# PIC18F24Q10 register map
Vendor: Microchip
Registers are 8-bit, read-write, reset 0x0 unless marked. A register's access mark holds for its fields unless they carry their own. Addresses are absolute, and some are shared; only a register's first bit layout is shown; [hi:lo] are bit positions; {n}, {i} and the like mark numbered series.

## math_progcrc
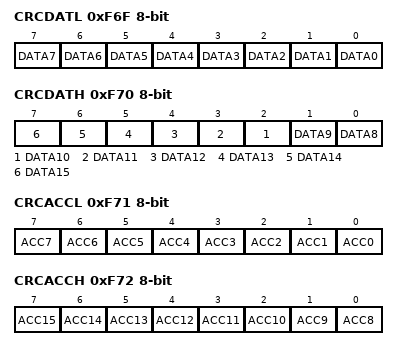
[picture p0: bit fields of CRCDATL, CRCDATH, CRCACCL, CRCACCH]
0xF6F CRCDATL reset not defined — (power-on value xxxxxxxx)
  [n] DATA{n} (n=0..7)
0xF70 CRCDATH reset not defined — (power-on value xxxxxxxx)
  [n-8] DATA{n} (n=8..15)
0xF71 CRCACCL
  [n] ACC{n} (n=0..7)
0xF72 CRCACCH
  [n-8] ACC{n} (n=8..15)
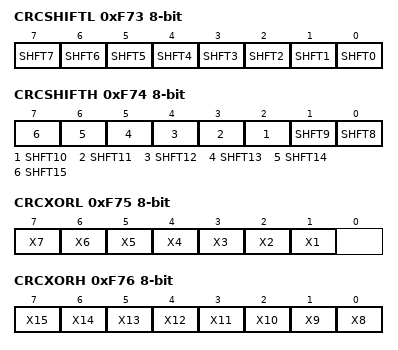
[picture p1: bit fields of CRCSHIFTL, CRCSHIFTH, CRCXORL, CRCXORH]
0xF73 CRCSHIFTL ro
  [n] SHFT{n} (n=0..7)
0xF74 CRCSHIFTH ro
  [n-8] SHFT{n} (n=8..15)
0xF75 CRCXORL reset not defined — (power-on value xxxxxxx1)
  [n] X{n} (n=1..7)
0xF76 CRCXORH reset not defined — (power-on value xxxxxxxx)
  [n-8] X{n} (n=8..15)
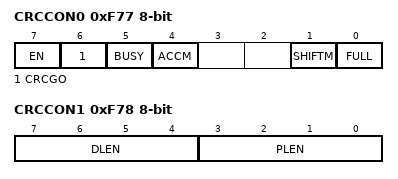
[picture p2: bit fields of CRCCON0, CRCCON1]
0xF77 CRCCON0
  [7] EN, [6] CRCGO, [5] BUSY ro, [4] ACCM, [1] SHIFTM, [0] FULL ro
0xF78 CRCCON1
  [7:4] DLEN, [3:0] PLEN

## mssp
0xF91 SSP1BUF reset not defined — (power-on value xxxxxxxx)
  [7:0] SSPBUF
0xF92 SSP1ADD
  [7:0] SSPADD
0xF93 SSP1MSK reset 0xFF
  [7:0] SSPMSK
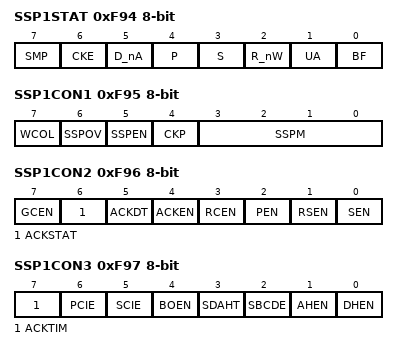
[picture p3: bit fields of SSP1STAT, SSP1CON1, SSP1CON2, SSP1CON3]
0xF94 SSP1STAT — MSSP1 STATUS REGISTER
  [7] SMP — SPI Data Input Sample Phase bit
  [6] CKE — SPI Clock Edge Select bit
  [5] D_nA ro — Data/Address bit
  [4] P ro — Stop bit
  [3] S ro — Start bit
  [2] R_nW ro — Read/Write Information bit
  [1] UA ro — Update Address bit
  [0] BF ro — Buffer Full Status bit (Receive mode only)
0xF95 SSP1CON1
  [7] WCOL — Write Collision Detect bit (Transmit mode only)
  [6] SSPOV — Receive Overflow Indicator bit
  [5] SSPEN — Synchronous Serial Port Enable bit
  [4] CKP — Clock Polarity Select bit
  [3:0] SSPM — Synchronous Serial Port Mode Select bits
0xF96 SSP1CON2
  [7] GCEN — General Call Enable bit (Slave mode only)
  [6] ACKSTAT ro — Acknowledge Status bit (Transmission only)
  [5] ACKDT — Acknowledge Data bit (Receive mode only)
  [4] ACKEN — Acknowledge Sequence Enable bit (Master Receive mode only)
  [3] RCEN — Receive Enable bit (Master mode only)
  [2] PEN — Stop Condition Enable bit (Master mode only)
  [1] RSEN — Repeated Start Condition Enable bit (Master mode only)
  [0] SEN — Start Condition Enable/Stretch Enable bit
0xF97 SSP1CON3
  [7] ACKTIM ro, [6] PCIE, [5] SCIE, [4] BOEN, [3] SDAHT, [2] SBCDE, [1] AHEN, [0] DHEN

## pwm
0xF9F PWM4DCL reset not defined — (power-on value xx------)
  [7:6] DC
0xFA0 PWM4DCH reset not defined — (power-on value xxxxxxxx)
  [7:0] DC
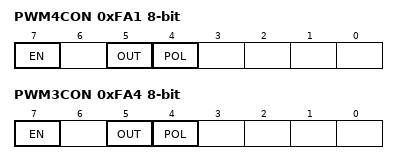
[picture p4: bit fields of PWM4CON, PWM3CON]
0xFA1 PWM4CON
  [7] EN, [5] OUT ro, [4] POL
0xFA2 PWM3DCL reset not defined — (power-on value xx------)
  [7:6] DC
0xFA3 PWM3DCH reset not defined — (power-on value xxxxxxxx)
  [7:0] DC
0xFA4 PWM3CON
  [7] EN, [5] OUT ro, [4] POL

## ccp
0xFA5 CCPR2L reset not defined — (power-on value xxxxxxxx)
  [7:0] RL
0xFA6 CCPR2H reset not defined — (power-on value xxxxxxxx)
  [7:0] RH
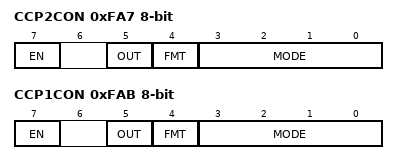
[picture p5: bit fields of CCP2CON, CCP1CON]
0xFA7 CCP2CON
  [7] EN, [5] OUT ro, [4] FMT, [3:0] MODE
0xFA8 CCP2CAP
  [1:0] CTS
0xFA9 CCPR1L reset not defined — (power-on value xxxxxxxx)
  [7:0] RL
0xFAA CCPR1H reset not defined — (power-on value xxxxxxxx)
  [7:0] RH
0xFAB CCP1CON
  [7] EN, [5] OUT ro, [4] FMT, [3:0] MODE
0xFAC CCP1CAP
  [1:0] CTS

## tmr
0xFAE T6TMR — 8-bit period timer
  [7:0] TMR6
0xFAF T6PR reset 0xFF
  [7:0] PR6
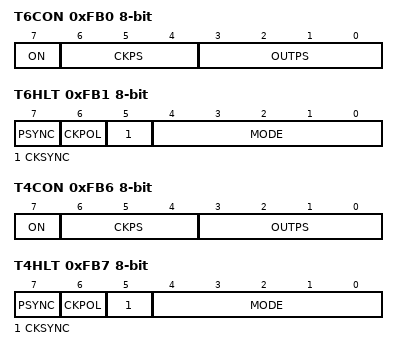
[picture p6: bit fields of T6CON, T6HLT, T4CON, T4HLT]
0xFB0 T6CON
  [7] ON, [6:4] CKPS, [3:0] OUTPS
0xFB1 T6HLT
  [7] PSYNC, [6] CKPOL, [5] CKSYNC, [4:0] MODE
0xFB2 T6CLKCON
  [3:0] CS
0xFB3 T6RST
  [3:0] RSEL
0xFB4 T4TMR — 8-bit period timer
  [7:0] TMR4
0xFB5 T4PR reset 0xFF
  [7:0] PR4
0xFB6 T4CON
  [7] ON, [6:4] CKPS, [3:0] OUTPS
0xFB7 T4HLT
  [7] PSYNC, [6] CKPOL, [5] CKSYNC, [4:0] MODE
0xFB8 T4CLKCON
  [3:0] CS
0xFB9 T4RST
  [3:0] RSEL
0xFBA T2TMR — 8-bit period timer
  [7:0] TMR2
0xFBB T2PR reset 0xFF
  [7:0] PR2
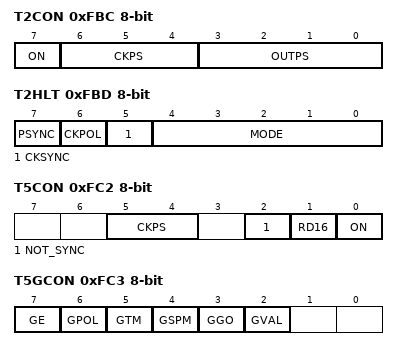
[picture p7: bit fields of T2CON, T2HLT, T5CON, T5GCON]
0xFBC T2CON
  [7] ON, [6:4] CKPS, [3:0] OUTPS
0xFBD T2HLT
  [7] PSYNC, [6] CKPOL, [5] CKSYNC, [4:0] MODE
0xFBE T2CLKCON
  [3:0] CS
0xFBF T2RST
  [3:0] RSEL
0xFC0 TMR5L
0xFC1 TMR5H
0xFC2 T5CON
  [5:4] CKPS, [2] NOT_SYNC, [1] RD16, [0] ON
0xFC3 T5GCON reset not defined — (power-on value 00000x--)
  [7] GE, [6] GPOL, [5] GTM, [4] GSPM, [3] GGO, [2] GVAL ro
0xFC4 T5GATE
  [3:0] GSS
0xFC5 T5CLK
  [3:0] CS
0xFC6 TMR3L
0xFC7 TMR3H
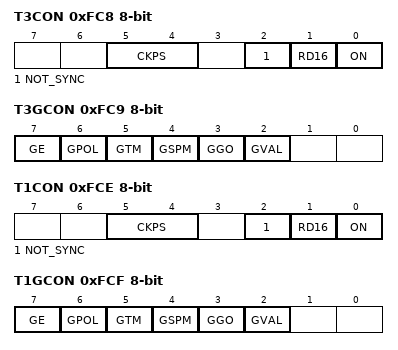
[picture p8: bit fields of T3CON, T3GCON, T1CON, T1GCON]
0xFC8 T3CON
  [5:4] CKPS, [2] NOT_SYNC, [1] RD16, [0] ON
0xFC9 T3GCON reset not defined — (power-on value 00000x--)
  [7] GE, [6] GPOL, [5] GTM, [4] GSPM, [3] GGO, [2] GVAL ro
0xFCA T3GATE
  [3:0] GSS
0xFCB T3CLK
  [3:0] CS
0xFCC TMR1L
0xFCD TMR1H
0xFCE T1CON
  [5:4] CKPS, [2] NOT_SYNC, [1] RD16, [0] ON
0xFCF T1GCON reset not defined — (power-on value 00000x--)
  [7] GE, [6] GPOL, [5] GTM, [4] GSPM, [3] GGO, [2] GVAL ro
0xFD0 T1GATE
  [3:0] GSS
0xFD1 T1CLK
  [3:0] CS
0xFD2 TMR0L
0xFD3 TMR0H reset 0xFF
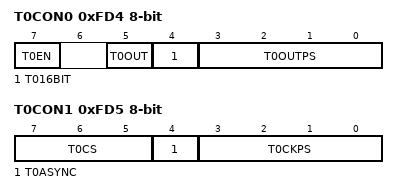
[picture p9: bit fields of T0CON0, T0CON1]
0xFD4 T0CON0
  [7] T0EN, [5] T0OUT ro, [4] T016BIT, [3:0] T0OUTPS
0xFD5 T0CON1
  [7:5] T0CS, [4] T0ASYNC, [3:0] T0CKPS
